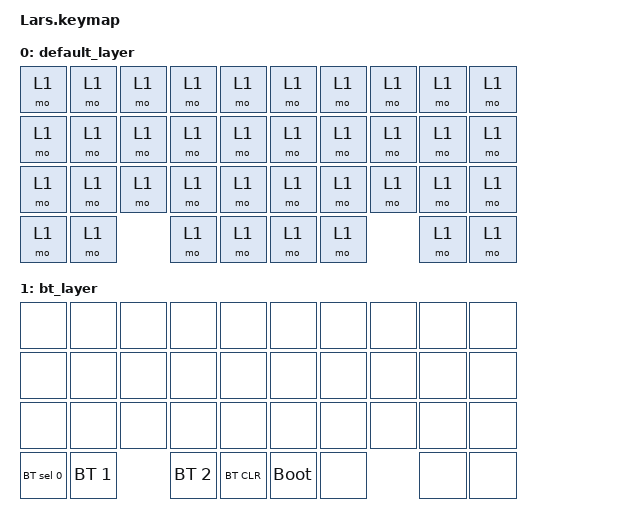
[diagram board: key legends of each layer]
#include <behaviors.dtsi>
#include <dt-bindings/zmk/keys.h>
#include <dt-bindings/zmk/bt.h>

/ {
  keymap{
    compatible = "zmk,keymap";

    default_layer {
      bindings = <
        &mo 1  &mo 1  &mo 1  &mo 1  &mo 1  &mo 1  &mo 1  &mo 1  &mo 1  &mo 1
        &mo 1  &mo 1  &mo 1  &mo 1  &mo 1  &mo 1  &mo 1  &mo 1  &mo 1  &mo 1
        &mo 1  &mo 1  &mo 1  &mo 1  &mo 1  &mo 1  &mo 1  &mo 1  &mo 1  &mo 1
        &mo 1  &mo 1         &mo 1  &mo 1  &mo 1  &mo 1         &mo 1  &mo 1
      >;
    };

    bt_layer {
      bindings = <
        &none          &none        &none  &none          &none        &none        &none  &none  &none  &none
        &none          &none        &none  &none          &none        &none        &none  &none  &none  &none
        &none          &none        &none  &none          &none        &none        &none  &none  &none  &none
        &bt BT_sel 0   &bt BT_SEL 1        &bt BT_SEL 2   &bt BT_CLR   &bootloader  &none         &none  &none
      >;
    };
  };
};
